# STM32F769NIH6 register map
File version: 1.0
Registers are 32-bit, access not given, reset 0x0 unless marked. A register's access mark holds for its fields unless they carry their own. Offsets are from the block's base; [hi:lo] are bit positions; {n}, {i} and the like mark numbered series; 'fields as' and 'values as' point back to an identical list.

## ADC1
Base 0x40012000
Same registers: ADC3 0x40012200
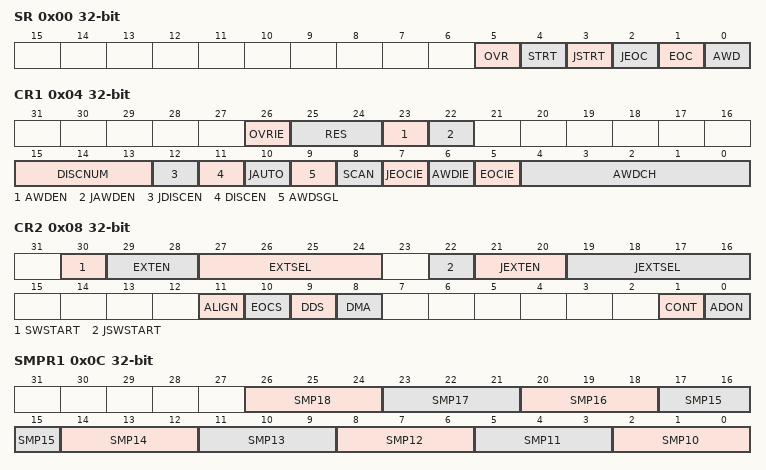
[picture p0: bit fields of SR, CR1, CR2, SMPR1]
0x00 SR
  [5] OVR, [4] STRT, [3] JSTRT, [2] JEOC, [1] EOC, [0] AWD
0x04 CR1
  [26] OVRIE, [25:24] RES, [23] AWDEN, [22] JAWDEN, [15:13] DISCNUM, [12] JDISCEN, [11] DISCEN, [10] JAUTO, [9] AWDSGL, [8] SCAN, [7] JEOCIE, [6] AWDIE, [5] EOCIE, [4:0] AWDCH
0x08 CR2
  [30] SWSTART, [29:28] EXTEN, [27:24] EXTSEL, [22] JSWSTART, [21:20] JEXTEN, [19:16] JEXTSEL, [11] ALIGN, [10] EOCS, [9] DDS, [8] DMA, [1] CONT, [0] ADON
0x0C SMPR1
  [3n-28:3n-30] SMP{n} (n=10..18)
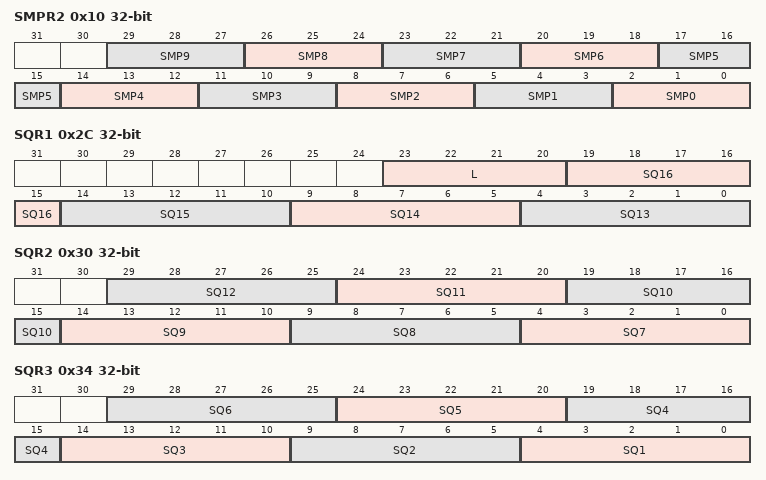
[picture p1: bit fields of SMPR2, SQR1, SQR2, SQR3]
0x10 SMPR2
  [3n+2:3n] SMP{n} (n=0..9)
{0x10+4i} JOFR{i} (i=1..4)
  [11:0] JOFFSET{i}
0x24 HTR
  [11:0] HT
0x28 LTR
  [11:0] LT
0x2C SQR1
  [23:20] L, [5n-61:5n-65] SQ{n} (n=13..16)
0x30 SQR2
  [5n-31:5n-35] SQ{n} (n=7..12)
0x34 SQR3
  [5n-1:5n-5] SQ{n} (n=1..6)
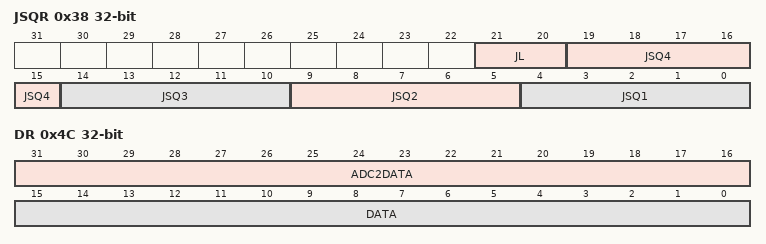
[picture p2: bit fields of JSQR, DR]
0x38 JSQR
  [21:20] JL, [5n-1:5n-5] JSQ{n} (n=1..4)
{0x38+4i} JDR{i} (i=1..4)
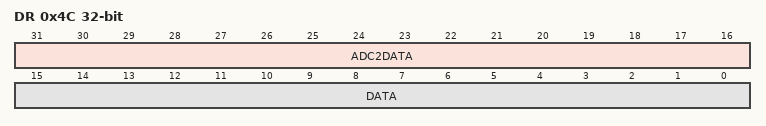
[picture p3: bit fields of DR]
0x4C DR
  [31:16] ADC2DATA, [15:0] DATA

## ADC2
Base 0x40012100
Registers as ADC1; these are added or differ:
0x4C DR
  [31:16] ADC2DATA, [15:0] DATA

## ADC
Base 0x40012300
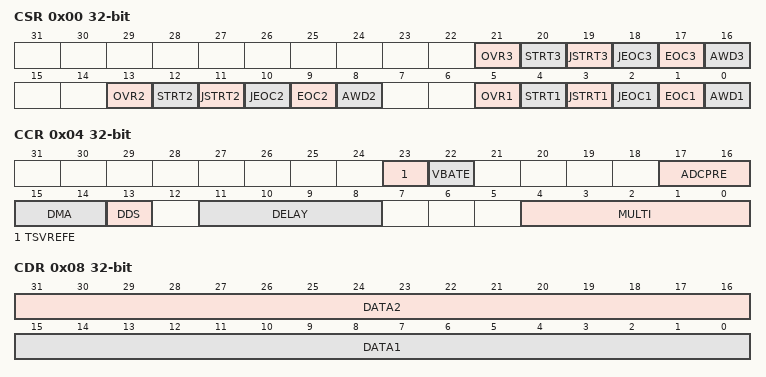
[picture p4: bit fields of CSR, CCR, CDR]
0x00 CSR
  [21] OVR3, [20] STRT3, [19] JSTRT3, [18] JEOC3, [17] EOC3, [16] AWD3, [13] OVR2, [12] STRT2, [11] JSTRT2, [10] JEOC2, [9] EOC2, [8] AWD2, [5] OVR1, [4] STRT1, [3] JSTRT1, [2] JEOC1, [1] EOC1, [0] AWD1
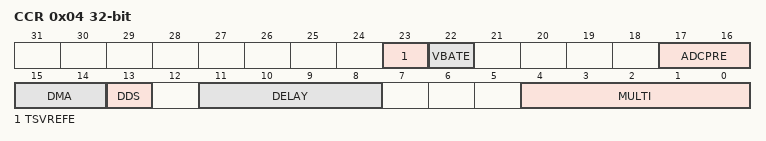
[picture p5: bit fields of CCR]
0x04 CCR
  [23] TSVREFE, [22] VBATE, [17:16] ADCPRE, [15:14] DMA, [13] DDS, [11:8] DELAY, [4:0] MULTI
0x08 CDR
  [31:16] DATA2, [15:0] DATA1

## ADC123_COMMON
Base 0x40012300
Registers as ADC; these are added or differ:
0x04 CCR
  [23] TSVREFE, [22] VBATE, [17:16] ADCPRE, [15:14] DMA, [13] DDS, [11:8] DELAY, [4:0] MULTI

## SYSCFG
Base 0x40013800
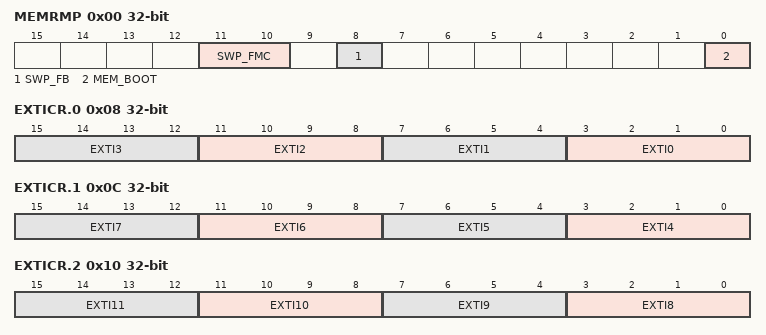
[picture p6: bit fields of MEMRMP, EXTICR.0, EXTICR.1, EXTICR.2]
0x00 MEMRMP
  [11:10] SWP_FMC, [8] SWP_FB, [0] MEM_BOOT
0x04 PMC
  [23] MII_RMII_SEL, [18] ADC3DC2, [17] ADC2DC2, [18:16] ADCxDC2, [n-2] I2C_PB{n}_FMP (n=6..9), [n-1] I2C{n}_FMP (n=1..4)
0x08 EXTICR.0
  [4n+3:4n] EXTI{n} (n=0..3)
0x0C EXTICR.1
  [4n-13:4n-16] EXTI{n} (n=4..7)
0x10 EXTICR.2
  [4n-29:4n-32] EXTI{n} (n=8..11)
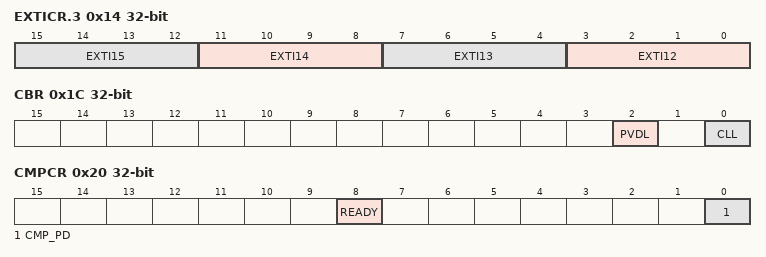
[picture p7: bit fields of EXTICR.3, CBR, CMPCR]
0x14 EXTICR.3
  [4n-45:4n-48] EXTI{n} (n=12..15)
0x1C CBR
  [2] PVDL, [0] CLL
0x20 CMPCR
  [8] READY, [0] CMP_PD

## EXTI
Base 0x40013C00
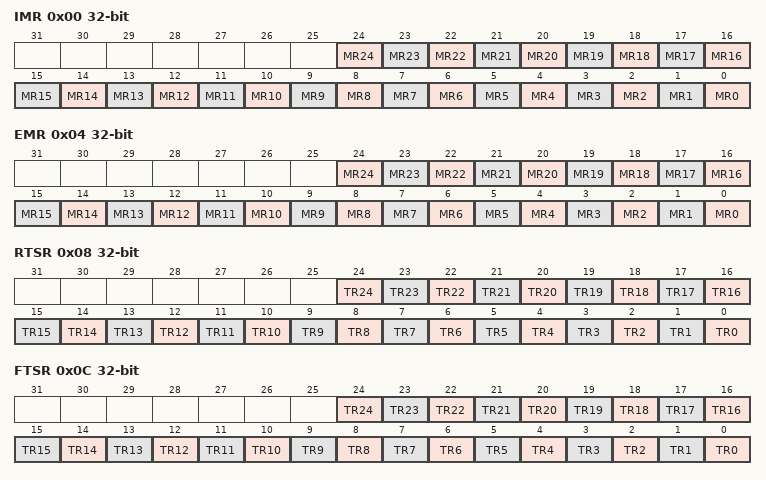
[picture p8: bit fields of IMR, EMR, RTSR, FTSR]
0x00 IMR
  [n] MR{n} (n=0..24)
0x04 EMR
  [n] MR{n} (n=0..24)
0x08 RTSR
  [n] TR{n} (n=0..24)
0x0C FTSR
  [n] TR{n} (n=0..24)
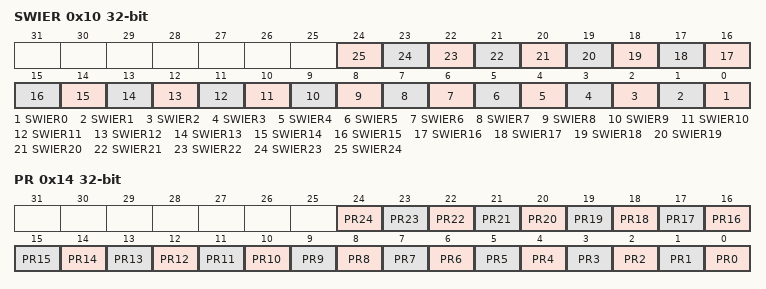
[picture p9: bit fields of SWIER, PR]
0x10 SWIER
  [n] SWIER{n} (n=0..24)
0x14 PR
  [n] PR{n} (n=0..24)

## SAI1
Base 0x40015800
Same registers: SAI2 0x40015C00
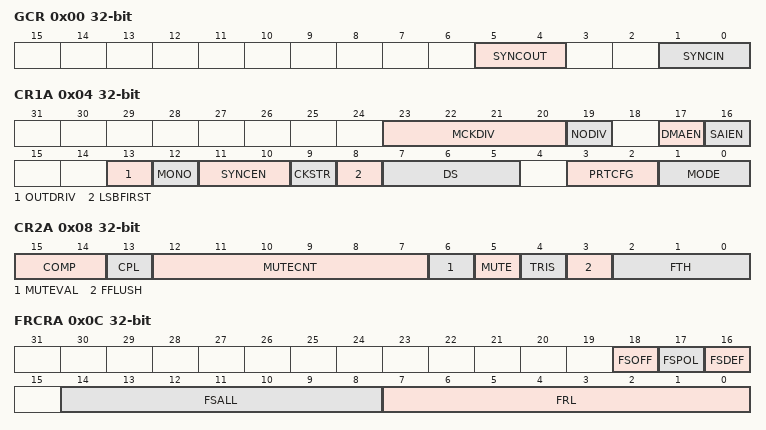
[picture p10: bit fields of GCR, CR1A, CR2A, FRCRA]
0x00 GCR
  [5:4] SYNCOUT, [1:0] SYNCIN
0x04 CR1A
  [23:20] MCKDIV, [19] NODIV, [17] DMAEN, [16] SAIEN, [13] OUTDRIV, [12] MONO, [11:10] SYNCEN, [9] CKSTR, [8] LSBFIRST, [7:5] DS, [3:2] PRTCFG, [1:0] MODE
0x08 CR2A
  [15:14] COMP, [13] CPL, [12:7] MUTECNT, [6] MUTEVAL, [5] MUTE, [4] TRIS, [3] FFLUSH, [2:0] FTH
0x0C FRCRA
  [18] FSOFF, [17] FSPOL, [16] FSDEF, [14:8] FSALL, [7:0] FRL
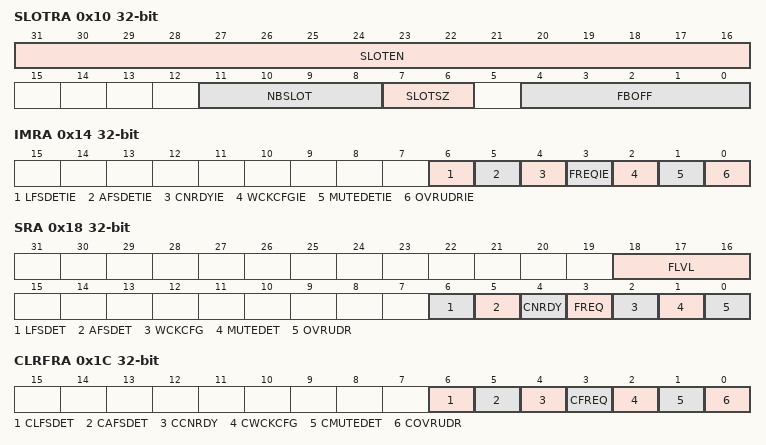
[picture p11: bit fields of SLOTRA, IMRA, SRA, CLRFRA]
0x10 SLOTRA
  [31:16] SLOTEN, [11:8] NBSLOT, [7:6] SLOTSZ, [4:0] FBOFF
0x14 IMRA
  [6] LFSDETIE, [5] AFSDETIE, [4] CNRDYIE, [3] FREQIE, [2] WCKCFGIE, [1] MUTEDETIE, [0] OVRUDRIE
0x18 SRA
  [18:16] FLVL, [6] LFSDET, [5] AFSDET, [4] CNRDY, [3] FREQ, [2] WCKCFG, [1] MUTEDET, [0] OVRUDR
0x1C CLRFRA
  [6] CLFSDET, [5] CAFSDET, [4] CCNRDY, [3] CFREQ, [2] CWCKCFG, [1] CMUTEDET, [0] COVRUDR
0x20 DRA
  [31:0] DATA
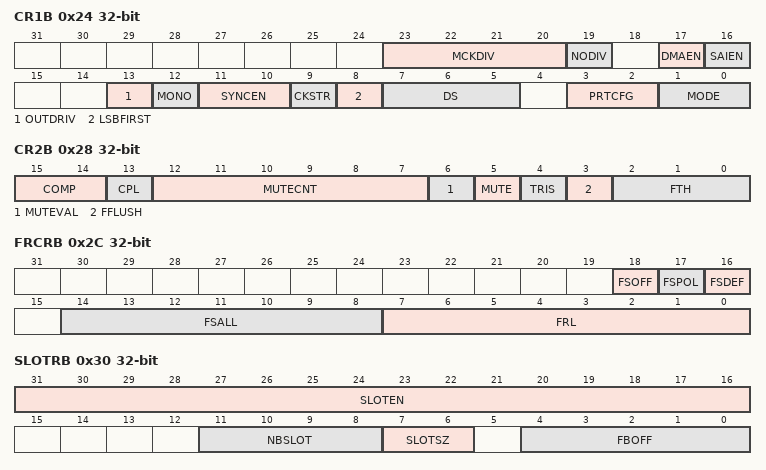
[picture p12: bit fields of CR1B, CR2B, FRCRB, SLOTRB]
0x24 CR1B
  fields as CR1A
0x28 CR2B
  fields as CR2A
0x2C FRCRB
  [18] FSOFF, [17] FSPOL, [16] FSDEF, [14:8] FSALL, [7:0] FRL
0x30 SLOTRB
  [31:16] SLOTEN, [11:8] NBSLOT, [7:6] SLOTSZ, [4:0] FBOFF
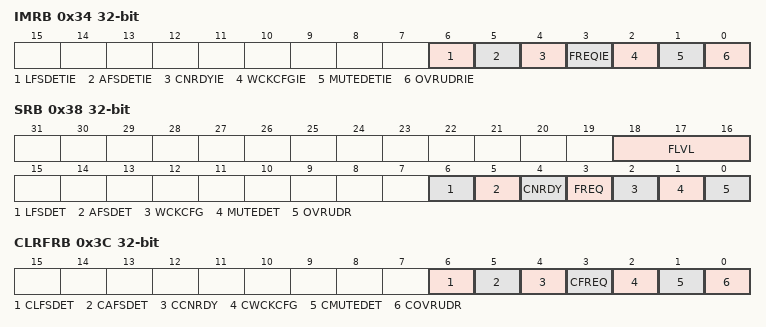
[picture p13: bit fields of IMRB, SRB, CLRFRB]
0x34 IMRB
  fields as IMRA
0x38 SRB
  fields as SRA
0x3C CLRFRB
  fields as CLRFRA
0x40 DRB
  [31:0] DATA

## LTDC
Base 0x40016800
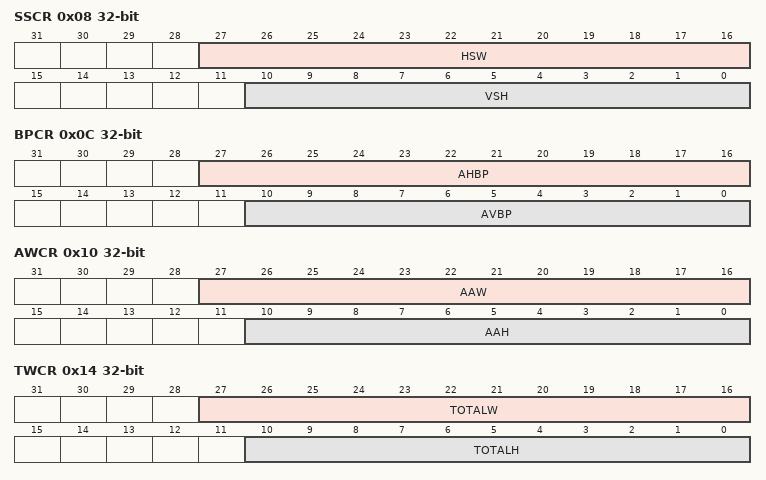
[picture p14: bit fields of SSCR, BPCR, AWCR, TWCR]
0x08 SSCR
  [27:16] HSW, [10:0] VSH
0x0C BPCR
  [27:16] AHBP, [10:0] AVBP
0x10 AWCR
  [27:16] AAW, [10:0] AAH
0x14 TWCR
  [27:16] TOTALW, [10:0] TOTALH
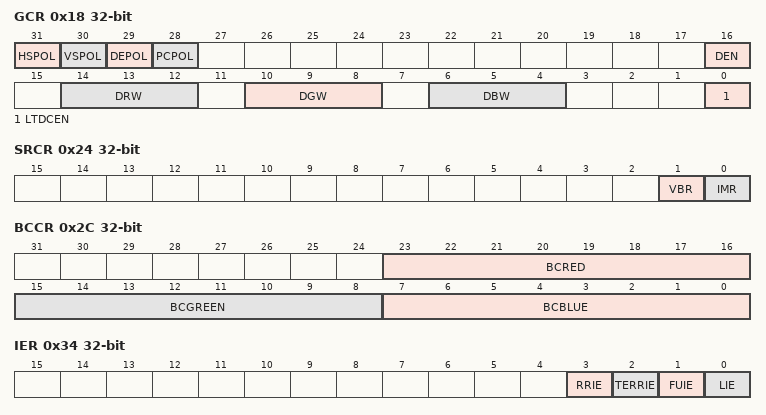
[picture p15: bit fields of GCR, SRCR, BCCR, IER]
0x18 GCR
  [31] HSPOL, [30] VSPOL, [29] DEPOL, [28] PCPOL, [16] DEN, [14:12] DRW, [10:8] DGW, [6:4] DBW, [0] LTDCEN
0x24 SRCR
  [1] VBR, [0] IMR
0x2C BCCR
  [23:16] BCRED, [15:8] BCGREEN, [7:0] BCBLUE
0x34 IER
  [3] RRIE, [2] TERRIE, [1] FUIE, [0] LIE
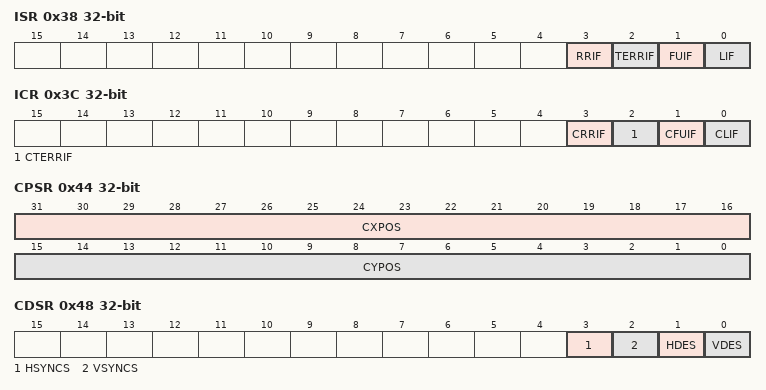
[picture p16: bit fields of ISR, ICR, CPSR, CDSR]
0x38 ISR
  [3] RRIF, [2] TERRIF, [1] FUIF, [0] LIF
0x3C ICR
  [3] CRRIF, [2] CTERRIF, [1] CFUIF, [0] CLIF
0x40 LIPCR
  [10:0] LIPOS
0x44 CPSR
  [31:16] CXPOS, [15:0] CYPOS
0x48 CDSR
  [3] HSYNCS, [2] VSYNCS, [1] HDES, [0] VDES
0x84 CR1
0x88 WHPCR1
0x8C WVPCR1
0x90 CKCR1
0x94 PFCR1
0x98 CACR1
0x9C DCCR1
0xA0 BFCR1
0xAC CFBAR1
0xB0 CFBLR1
0xB4 CFBLNR1
0xC4 CLUTWR1
0x104 CR2
0x108 WHPCR2
0x10C WVPCR2
0x110 CKCR2
0x114 PFCR2
0x118 CACR2
0x11C DCCR2
0x120 BFCR2
0x12C CFBAR2
0x130 CFBLR2
0x134 CFBLNR2
0x144 CLUTWR2
